# AC7802x register map
Vendor: AutoChips; Series: AC78; File version: 1.0
CPU: CM0PLUS r0p1, little endian, no MPU, no FPU, VTOR, 2 interrupt priority bits
Registers are 32-bit, read-write, reset 0x0 unless marked. A register's access mark holds for its fields unless they carry their own. Offsets are from the block's base; [hi:lo] are bit positions.

## ANA_RG — Analog Register
Base 0x40008800
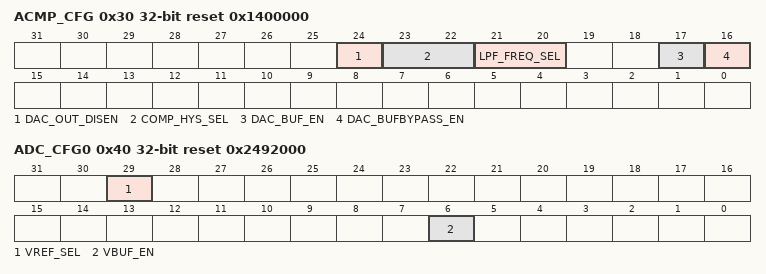
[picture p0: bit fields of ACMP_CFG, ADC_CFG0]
0x30 ACMP_CFG reset 0x1400000 — ACMP Configure Register
  [24] DAC_OUT_DISEN
    0=enable dac output; 1=disable dac output
  [23:22] COMP_HYS_SEL — hysteresis voltage select
    0=bypass; 1=10mV; 2=20mV; 3=40mV
  [21:20] LPF_FREQ_SEL — low-pass filter select
    0=500K; 1=1M; 2=2M; 3=bypass
  [17] DAC_BUF_EN — DAC buffer enable
    0=disable; 1=enable
  [16] DAC_BUFBYPASS_EN — DAC buffer bypass
    0=bypass disable; 1=bypass enable
0x40 ADC_CFG0 reset 0x2492000 — ADC Configure Register 0
  [29] VREF_SEL — ADC Reference voltage source select
    0=External voltage; 1=AVDD50 power supply
  [6] VBUF_EN — BG & TS Buffer enable
    0=disable; 1=enable
0x44 ADC_CFG1 — ADC Configure Register 1
  [31:30] MON_SEL — Internal Monitor channel select
    0=BG; 1=Tsensor

## PWDT — Pulse Width Detection Timer
Base 0x40017000
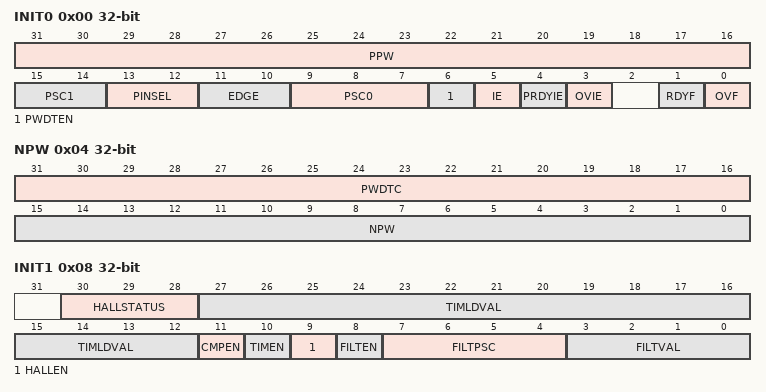
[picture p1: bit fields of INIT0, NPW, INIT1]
0x00 INIT0 — PWDT Initialize Register 0
  [31:16] PPW ro — Positive Pulse Width
  [15:14] PSC1 — PWDT Clock Prescaler 1
    0=Clock divided by 1; 1=Clock divided by 2; 2=Clock divided by 4
  [13:12] PINSEL — PWDT Pulse Inputs Selection
    0=PWDTIN[0] as input; 1=PWDTIN[1] as input; 2=PWDTIN[2] as input; 3=ACMP OUT as input
  [11:10] EDGE — PWDT Input Edge Sensitivity
    0=The first falling-edge starts the pulse width measurement, and on all the subsequent falling edges, the pulse width is captured; 1=The first rising edge starts the pulse width measurement, and on all the subsequent rising and falling edges, the pulse width is captured; 2=The first falling edge starts the pulse width measurement, and on all the subsequent rising and falling edges, the pulse width is captured; 3=The first-rising edge starts the pulse width measurement, and on all the subsequent rising edges, the pulse width is captured
  [9:7] PSC0 — PWDT Clock Prescaler 0
    0=Clock divided by 1; 1=Clock divided by 2; 2=Clock divided by 4; 3=Clock divided by 8; 4=Clock divided by 16; 5=Clock divided by 32; 6=Clock divided by 64; 7=Clock divided by 128
  [6] PWDTEN — PWDT Module Enable
    0=PWDT disabled; 1=PWDT enabled
  [5] IE — PWDT Module Interrupt Enable
    0=Disable interrupt; 1=Enable interrupt
  [4] PRDYIE — PWDT Pulse Width Data Ready Interrupt Enable
    0=Disable interrupt; 1=Enable interrupt
  [3] OVIE — PWDT Counter Overflow Interrupt Enable
    0=Disable interrupt; 1=Enable interrupt
  [1] RDYF — PWDT Pulse Width Ready Flag
    0=PWDT pulse width register is not up-to-date; 1=PWDT pulse width register has been updated
  [0] OVF — PWDT Counter Overflow flag
    0=Counter no overflow; 1=Counter overflow
0x04 NPW ro — Negative Pulse Width
  [31:16] PWDTC — PWDT Counter
  [15:0] NPW — Negative Pulse Width
0x08 INIT1 — Pulse Width Detection Timer Initialize Register 1
  [30:28] HALLSTATUS ro — HALL Sensor Status Value
  [27:12] TIMLDVAL — PWDT Timer Load Value
  [11] CMPEN — PWDT Compare Mode Enable Bit
    0=Set the pwt_in0 ~ pwt_in2 derived from pad pwt_in0 ~ pwt_in2; 1=Set the pwt_in0 ~ pwt_in2 derived from acmp0_pwt_a ~ acmp0_pwt_c
  [10] TIMEN — PWDT Timer Function Enable Bit
    0=PWDT Timer Function Disable; 1=PWDT Timer Function Enable
  [9] HALLEN — Hall Sensor Signal Detect function Enable Bit
    0=Hall Sensor Signal Detect function Disable; 1=Hall Sensor Signal Detect function Enable
  [8] FILTEN — PWDT input filter function Enable Bit
    0=Filter disable; 1=Filter enable
  [7:4] FILTPSC — PWDT input filter prescaler
  [3:0] FILTVAL — PWDT filter Value

## TIMER_CTRL — Timer Control
Base 0x40011000
0x00 MCR reset 0x2 — Timer Module Control Regitser
  [1] MDIS — Timers Module Disable
    0=Timers enabled; 1=Timers disabled
